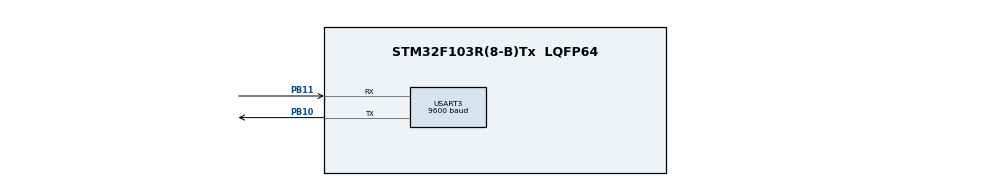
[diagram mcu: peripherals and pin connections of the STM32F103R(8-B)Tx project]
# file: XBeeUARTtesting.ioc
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Mcu.Family=STM32F1
Mcu.Name=STM32F103R(8-B)Tx
Mcu.Package=LQFP64
NVIC.PriorityGroup=NVIC_PRIORITYGROUP_4
NVIC.USART3_IRQn=true\:0\:0\:false\:false\:true\:true\:true
PA13.Mode=Serial_Wire
PA13.Signal=SYS_JTMS-SWDIO
PA14.Mode=Serial_Wire
PA14.Signal=SYS_JTCK-SWCLK
PB10.Mode=Asynchronous
PB10.Signal=USART3_TX
PB11.Mode=Asynchronous
PB11.Signal=USART3_RX
ProjectManager.HeapSize=0x200
ProjectManager.StackSize=0x400
ProjectManager.TargetToolchain=STM32CubeIDE
RCC.APB1Freq_Value=8000000
RCC.APB2Freq_Value=8000000
USART3.BaudRate=9600
USART3.VirtualMode=VM_ASYNC
board=custom

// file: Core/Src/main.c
/* USER CODE BEGIN Header */
/**
  ******************************************************************************
  * @file           : main.c
  * @brief          : Main program body
  ******************************************************************************
  * @attention
  *
  * <h2><center>&copy; Copyright (c) 2021 STMicroelectronics.
  * All rights reserved.</center></h2>
  *
  * This software component is licensed by ST under BSD 3-Clause license,
  * the "License"; You may not use this file except in compliance with the
  * License. You may obtain a copy of the License at:
  *                        opensource.org/licenses/BSD-3-Clause
  *
  ******************************************************************************
  */
/* USER CODE END Header */
#include "main.h"

/* USER CODE BEGIN Includes */
#include "sensorObjects.h"
/* USER CODE END Includes */

UART_HandleTypeDef huart3;

/* USER CODE BEGIN PV */
//uint16_t xbeeIODataLines[2];

/* USER CODE END PV */

void SystemClock_Config(void);
static void MX_GPIO_Init(void);
static void MX_USART3_UART_Init(void);

int main(void)
{

  /* MCU Configuration--------------------------------------------------------*/

  /* Reset of all peripherals, Initializes the Flash interface and the Systick. */
  HAL_Init();

  /* Configure the system clock */
  SystemClock_Config();

  /* Initialize all configured peripherals */
  MX_GPIO_Init();
  MX_USART3_UART_Init();
  /* USER CODE BEGIN 2 */
 initializeNodes();
uartInterruptInit(26);

  /* USER CODE END 2 */

  /* Infinite loop */
  while (1)
  {

  }
}

void SystemClock_Config(void)
{
  RCC_OscInitTypeDef RCC_OscInitStruct = {0};
  RCC_ClkInitTypeDef RCC_ClkInitStruct = {0};

  /** Initializes the RCC Oscillators according to the specified parameters
  * in the RCC_OscInitTypeDef structure.
  */
  RCC_OscInitStruct.OscillatorType = RCC_OSCILLATORTYPE_HSI;
  RCC_OscInitStruct.HSIState = RCC_HSI_ON;
  RCC_OscInitStruct.HSICalibrationValue = RCC_HSICALIBRATION_DEFAULT;
  RCC_OscInitStruct.PLL.PLLState = RCC_PLL_NONE;
  if (HAL_RCC_OscConfig(&RCC_OscInitStruct) != HAL_OK)
  {
    Error_Handler();
  }
  /** Initializes the CPU, AHB and APB buses clocks
  */
  RCC_ClkInitStruct.ClockType = RCC_CLOCKTYPE_HCLK|RCC_CLOCKTYPE_SYSCLK
                              |RCC_CLOCKTYPE_PCLK1|RCC_CLOCKTYPE_PCLK2;
  RCC_ClkInitStruct.SYSCLKSource = RCC_SYSCLKSOURCE_HSI;
  RCC_ClkInitStruct.AHBCLKDivider = RCC_SYSCLK_DIV1;
  RCC_ClkInitStruct.APB1CLKDivider = RCC_HCLK_DIV1;
  RCC_ClkInitStruct.APB2CLKDivider = RCC_HCLK_DIV1;

  if (HAL_RCC_ClockConfig(&RCC_ClkInitStruct, FLASH_LATENCY_0) != HAL_OK)
  {
    Error_Handler();
  }
}

static void MX_USART3_UART_Init(void)
{

  huart3.Instance = USART3;
  huart3.Init.BaudRate = 9600;
  huart3.Init.WordLength = UART_WORDLENGTH_8B;
  huart3.Init.StopBits = UART_STOPBITS_1;
  huart3.Init.Parity = UART_PARITY_NONE;
  huart3.Init.Mode = UART_MODE_TX_RX;
  huart3.Init.HwFlowCtl = UART_HWCONTROL_NONE;
  huart3.Init.OverSampling = UART_OVERSAMPLING_16;
  if (HAL_UART_Init(&huart3) != HAL_OK)
  {
    Error_Handler();
  }

}

static void MX_GPIO_Init(void)
{

  /* GPIO Ports Clock Enable */
  __HAL_RCC_GPIOB_CLK_ENABLE();
  __HAL_RCC_GPIOA_CLK_ENABLE();

}

/* USER CODE BEGIN 4 */
void uartInterruptInit(uint8_t length)
{
	//has to stay with main (the file where the "UART_HandleTypeDef huart3;" is)
	HAL_UART_Receive_IT(&huart3, &uartBufferRX[0], length);

	return;
}

void uartTransmit(uint8_t *buffer, uint8_t length)
{
	//has to stay with main (the file where the "UART_HandleTypeDef huart3;" is)
	HAL_UART_Transmit(&huart3, buffer, length, 1);

	return;
}

void HAL_UART_RxCpltCallback(UART_HandleTypeDef * huart)
{
	//has to stay with main (the file where the "UART_HandleTypeDef huart3;" is)
	if (uartBufferRX[0] == 0x7E)
	{
		switch (uartBufferRX[3])
		{
		case 0x92:
			processIO(uartBufferRX);
			break;

		case 0x97:
			processATResponse(uartBufferRX);
			break;

		default://if it wasnt an expected data type just throw it out
			uartInterruptInit(26);
			break;
		}
	}

	return;
}
/* USER CODE END 4 */

void Error_Handler(void)
{
}

/************************ (C) COPYRIGHT STMicroelectronics *****END OF FILE****/
